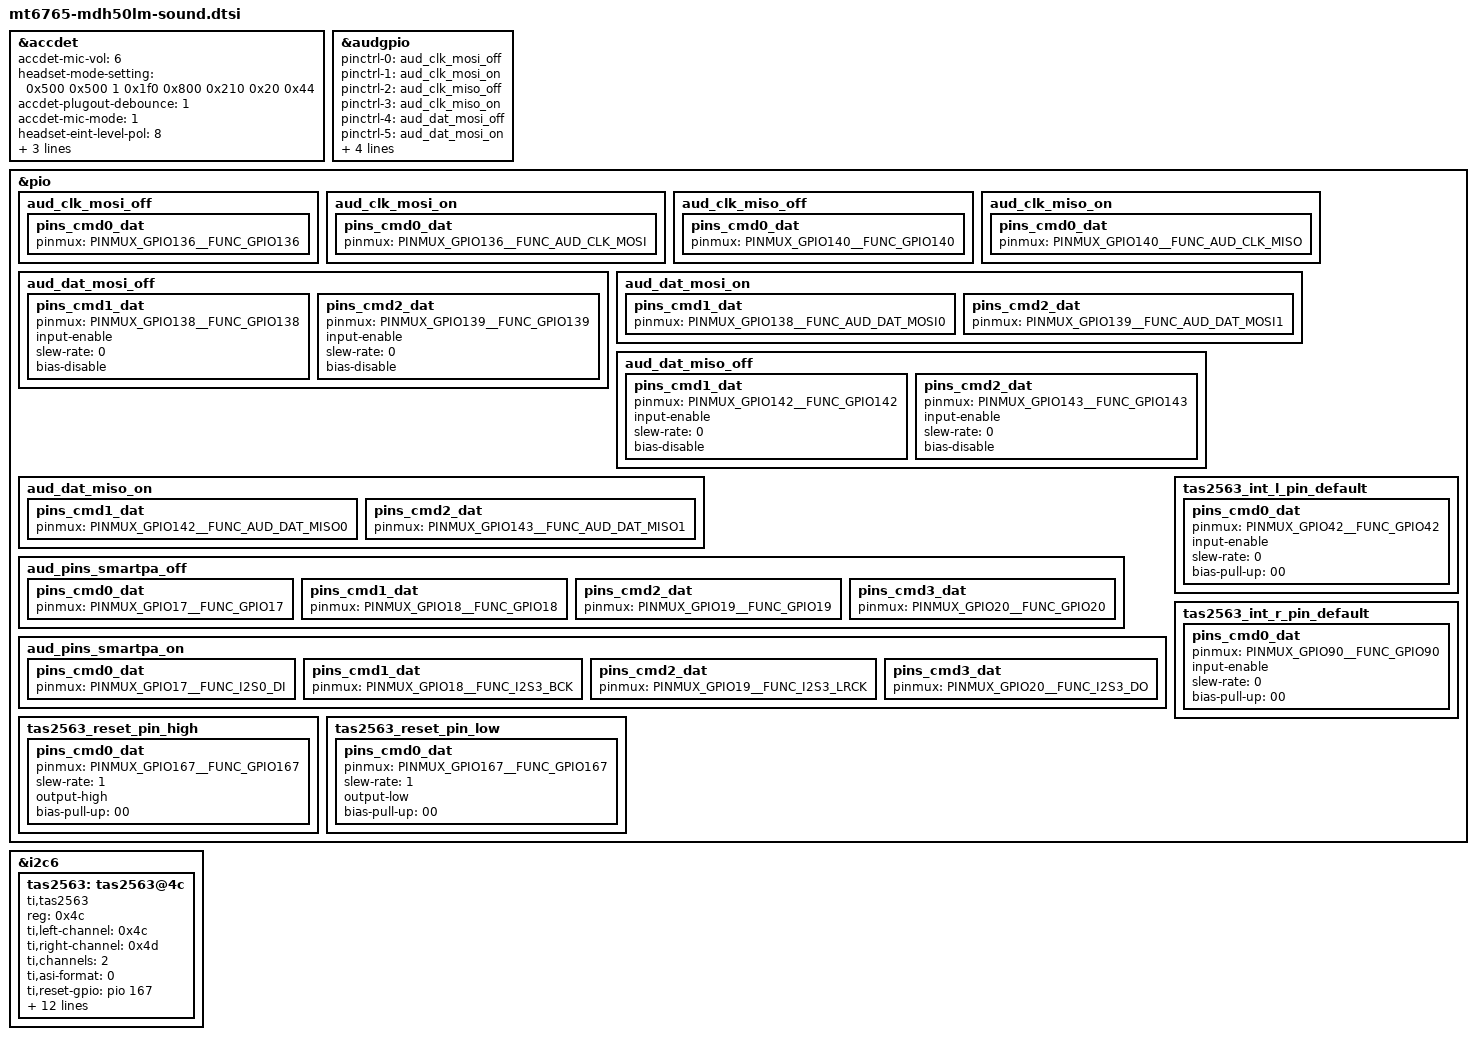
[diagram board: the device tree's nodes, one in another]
/*
 * LG Electronics MT6765 HDK sound device tree source
 *
 * Copyright (c) 2018 LG Electronics Co., Ltd.
 *              http://www.lge.com
 *
 */

/* accdet start */
&accdet {
    accdet-mic-vol = <6>;
    headset-mode-setting = <0x500 0x500 1 0x1f0 0x800 0x210 0x20 0x44>;
    accdet-plugout-debounce = <1>;
    accdet-mic-mode = <1>;
    headset-eint-level-pol = <8>;
    headset-three-key-threshold = <0 80 220 400>;
    headset-three-key-threshold-CDD = <0 121 192 600>;
    headset-four-key-threshold = <0 58 110 192 400>;
    status = "okay";
};
/* accdet end */

/* AUDIO GPIO standardization */
&audgpio {
    pinctrl-names = "aud_clk_mosi_off",
            "aud_clk_mosi_on",
            "aud_clk_miso_off",
            "aud_clk_miso_on",
            "aud_dat_mosi_off",
            "aud_dat_mosi_on",
            "aud_dat_miso_off",
            "aud_dat_miso_on",
            "aud_smartpa_off",
            "aud_smartpa_on";
    pinctrl-0 = <&aud_clk_mosi_off>;
    pinctrl-1 = <&aud_clk_mosi_on>;
    pinctrl-2 = <&aud_clk_miso_off>;
    pinctrl-3 = <&aud_clk_miso_on>;
    pinctrl-4 = <&aud_dat_mosi_off>;
    pinctrl-5 = <&aud_dat_mosi_on>;
    pinctrl-6 = <&aud_dat_miso_off>;
    pinctrl-7 = <&aud_dat_miso_on>;
    pinctrl-8 = <&aud_pins_smartpa_off>;
    pinctrl-9 = <&aud_pins_smartpa_on>;
    status = "okay";
};

&pio {
    aud_clk_mosi_off: aud_clk_mosi_off {
        pins_cmd0_dat {
            pinmux = <PINMUX_GPIO136__FUNC_GPIO136>;
        };
    };

    aud_clk_mosi_on: aud_clk_mosi_on {
        pins_cmd0_dat {
            pinmux = <PINMUX_GPIO136__FUNC_AUD_CLK_MOSI>;
        };
    };

    aud_clk_miso_off: aud_clk_miso_off {
        pins_cmd0_dat {
            pinmux = <PINMUX_GPIO140__FUNC_GPIO140>;
        };
    };

    aud_clk_miso_on: aud_clk_miso_on {
        pins_cmd0_dat {
            pinmux = <PINMUX_GPIO140__FUNC_AUD_CLK_MISO>;
        };
    };

    aud_dat_mosi_off: aud_dat_mosi_off {
        pins_cmd1_dat {
            pinmux = <PINMUX_GPIO138__FUNC_GPIO138>;
            input-enable;
            slew-rate = <0>;
            bias-disable;
        };
        pins_cmd2_dat {
            pinmux = <PINMUX_GPIO139__FUNC_GPIO139>;
            input-enable;
            slew-rate = <0>;
            bias-disable;
        };
    };

    aud_dat_mosi_on: aud_dat_mosi_on {
        pins_cmd1_dat {
            pinmux = <PINMUX_GPIO138__FUNC_AUD_DAT_MOSI0>;
        };
        pins_cmd2_dat {
            pinmux = <PINMUX_GPIO139__FUNC_AUD_DAT_MOSI1>;
        };
    };

    aud_dat_miso_off: aud_dat_miso_off {
        pins_cmd1_dat {
            pinmux = <PINMUX_GPIO142__FUNC_GPIO142>;
            input-enable;
            slew-rate = <0>;
            bias-disable;
        };
        pins_cmd2_dat {
            pinmux = <PINMUX_GPIO143__FUNC_GPIO143>;
            input-enable;
            slew-rate = <0>;
            bias-disable;
        };
    };

    aud_dat_miso_on: aud_dat_miso_on {
        pins_cmd1_dat {
            pinmux = <PINMUX_GPIO142__FUNC_AUD_DAT_MISO0>;
        };
        pins_cmd2_dat {
            pinmux = <PINMUX_GPIO143__FUNC_AUD_DAT_MISO1>;
        };
    };

    aud_pins_smartpa_off: aud_pins_smartpa_off {
        pins_cmd0_dat {
            pinmux = <PINMUX_GPIO17__FUNC_GPIO17>;
        };
        pins_cmd1_dat {
            pinmux = <PINMUX_GPIO18__FUNC_GPIO18>;
        };
        pins_cmd2_dat {
            pinmux = <PINMUX_GPIO19__FUNC_GPIO19>;
        };
        pins_cmd3_dat {
            pinmux = <PINMUX_GPIO20__FUNC_GPIO20>;
        };
    };

    aud_pins_smartpa_on: aud_pins_smartpa_on {
        pins_cmd0_dat {
            pinmux = <PINMUX_GPIO17__FUNC_I2S0_DI>;
        };
        pins_cmd1_dat {
            pinmux = <PINMUX_GPIO18__FUNC_I2S3_BCK>;
        };
        pins_cmd2_dat {
            pinmux = <PINMUX_GPIO19__FUNC_I2S3_LRCK>;
        };
        pins_cmd3_dat {
            pinmux = <PINMUX_GPIO20__FUNC_I2S3_DO>;
        };
    };
};

&i2c6 {
    tas2563:tas2563@4c {
        compatible = "ti,tas2563";
        reg = <0x4c>;
        ti,left-channel = <0x4c>;
        ti,right-channel = <0x4d>;
        ti,channels = <2>;
        ti,asi-format = <0>; /* 0, i2S; 1, DSP;  */
        ti,reset-gpio = <&pio 167 0>;
        ti,irq-gpio = <&pio 42 0>;
        ti,irq-gpio2 = <&pio 90 0>;
        ti,left-slot = <0>; /* <left slot number> */
        ti,right-slot = <4>; /* <right slot number> */
        ti,echo-ref = <2>;
        ti,i2s-bits = <16>;
        ti,imon-slot-no = <0>; /* <current sense slot number> */
        ti,vmon-slot-no = <2>; /* <current voltage slot number> */
        pinctrl-names = "default_l", "default_r", "reset_high", "reset_low";
        pinctrl-0 = <&tas2563_int_l_pin_default>;
        pinctrl-1 = <&tas2563_int_r_pin_default>;
        pinctrl-2 = <&tas2563_reset_pin_high>;
        pinctrl-3 = <&tas2563_reset_pin_low>;
        status = "ok";
    };
};

&pio {
    tas2563_int_l_pin_default: tas2563_int_l_pin_default {
        pins_cmd0_dat {
            pinmux = <PINMUX_GPIO42__FUNC_GPIO42>;
            input-enable;
            slew-rate = <0>;
            bias-pull-up = <00>;
        };
    };

    tas2563_int_r_pin_default: tas2563_int_r_pin_default {
        pins_cmd0_dat {
            pinmux = <PINMUX_GPIO90__FUNC_GPIO90>;
            input-enable;
            slew-rate = <0>;
            bias-pull-up = <00>;
        };
    };
    tas2563_reset_pin_high: tas2563_reset_pin_high {
        pins_cmd0_dat {
            pinmux = <PINMUX_GPIO167__FUNC_GPIO167>;
            slew-rate = <1>;
            output-high;
            bias-pull-up = <00>;
        };
    };
    tas2563_reset_pin_low: tas2563_reset_pin_low {
        pins_cmd0_dat {
            pinmux = <PINMUX_GPIO167__FUNC_GPIO167>;
            slew-rate = <1>;
            output-low;
            bias-pull-up = <00>;
        };
    };
};

/* AUDIO end */
